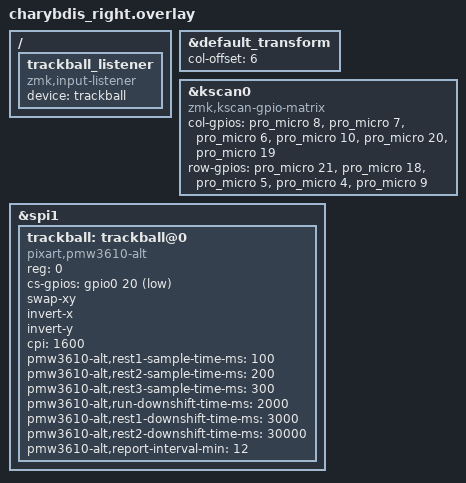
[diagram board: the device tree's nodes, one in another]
#include "charybdis.dtsi"
#include "charybdis_pmw3610.dtsi"

// The matrix transform is 6 columns over because the left half is 6 columns wide.
&default_transform {
	col-offset = <6>;
};

&kscan0 {
	compatible = "zmk,kscan-gpio-matrix";
	
	col-gpios
		= <&pro_micro  8 (GPIO_ACTIVE_HIGH | GPIO_PULL_DOWN)>
		, <&pro_micro  7 (GPIO_ACTIVE_HIGH | GPIO_PULL_DOWN)>
		, <&pro_micro  6 (GPIO_ACTIVE_HIGH | GPIO_PULL_DOWN)>
		, <&pro_micro 10 (GPIO_ACTIVE_HIGH | GPIO_PULL_DOWN)>
		, <&pro_micro 20 (GPIO_ACTIVE_HIGH | GPIO_PULL_DOWN)>
		, <&pro_micro 19 (GPIO_ACTIVE_HIGH | GPIO_PULL_DOWN)>
		;

	row-gpios
                = <&pro_micro 21  GPIO_ACTIVE_HIGH>
                , <&pro_micro 18  GPIO_ACTIVE_HIGH>
                , <&pro_micro 5  GPIO_ACTIVE_HIGH>
                , <&pro_micro 4  GPIO_ACTIVE_HIGH>
                , <&pro_micro 9 GPIO_ACTIVE_HIGH>
                ;
};

// --- ПРАВИЛЬНАЯ НАСТРОЙКА SPI И ТРЕКБОЛА ---

&spi1 {
    status = "okay";

    trackball: trackball@0 {
        compatible = "pixart,pmw3610-alt";
        reg = <0>;

        // ВАЖНО: проверь этот пин — на Charybdis это обычно GPIO 20 с LOW
        cs-gpios = <&gpio0 20 GPIO_ACTIVE_LOW>;

        swap-xy;
        invert-x;
        invert-y;

        cpi = <1600>;

        pmw3610-alt,rest1-sample-time-ms = <100>;
        pmw3610-alt,rest2-sample-time-ms = <200>;
        pmw3610-alt,rest3-sample-time-ms = <300>;
        pmw3610-alt,run-downshift-time-ms = <2000>;
        pmw3610-alt,rest1-downshift-time-ms = <3000>;
        pmw3610-alt,rest2-downshift-time-ms = <30000>;
        pmw3610-alt,report-interval-min = <12>;
    };
};

// Listener, который слушает именно этот узел
/ {
  trackball_listener {
    compatible = "zmk,input-listener";
    device = <&trackball>;
  };
};
